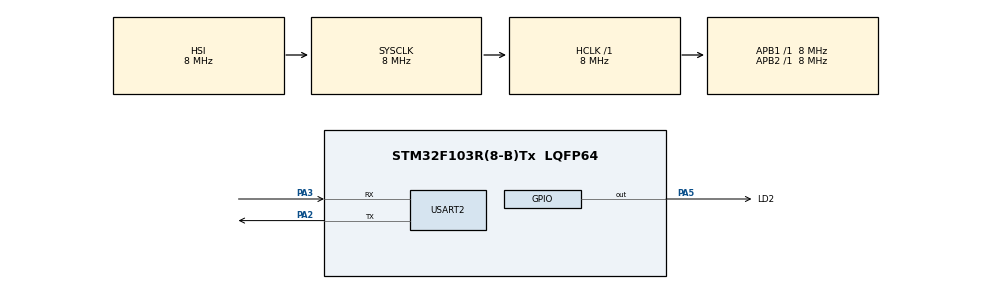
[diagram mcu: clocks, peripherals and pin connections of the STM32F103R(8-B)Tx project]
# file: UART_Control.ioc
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Mcu.Family=STM32F1
Mcu.Name=STM32F103R(8-B)Tx
Mcu.Package=LQFP64
NVIC.PriorityGroup=NVIC_PRIORITYGROUP_4
PA2.Mode=Asynchronous
PA2.Signal=USART2_TX
PA3.Mode=Asynchronous
PA3.Signal=USART2_RX
PA5.GPIO_Label=LD2
PA5.Signal=GPIO_Output
ProjectManager.HeapSize=0x200
ProjectManager.StackSize=0x400
ProjectManager.TargetToolchain=STM32CubeIDE
RCC.AHBFreq_Value=8000000
RCC.APB1Freq_Value=8000000
RCC.APB1TimFreq_Value=8000000
RCC.APB2Freq_Value=8000000
RCC.APB2TimFreq_Value=8000000
RCC.HCLKFreq_Value=8000000
RCC.SYSCLKFreq_VALUE=8000000
RCC.USBFreq_Value=8000000
USART2.VirtualMode=VM_ASYNC
VP_SYS_VS_ND.Mode=No_Debug
board=custom

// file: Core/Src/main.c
/* USER CODE BEGIN Header */
/**
  ******************************************************************************
  * @file           : main.c
  * @brief          : 01_UART_Control - LED control over USART2
  ******************************************************************************
  * @attention
  *
  * Copyright (c) 2026 STMicroelectronics.
  * All rights reserved.
  *
  ******************************************************************************
  */
/* USER CODE END Header */

#include "main.h"
#include <string.h>

UART_HandleTypeDef huart2;

void SystemClock_Config(void);
static void MX_GPIO_Init(void);
static void MX_USART2_UART_Init(void);

int main(void)
{

  HAL_Init();

  SystemClock_Config();

  MX_GPIO_Init();
  MX_USART2_UART_Init();
  /* USER CODE BEGIN 2 */
  const char *welcome = "\r\n=== 01_UART_Control ===\r\n"
                        "Send '1' to switch LED ON, '0' to switch LED OFF.\r\n";
  HAL_UART_Transmit(&huart2, (uint8_t *)welcome, strlen(welcome), HAL_MAX_DELAY);
  /* USER CODE END 2 */

  /* Infinite loop */
  /* USER CODE BEGIN WHILE */
  uint8_t rx;
  while (1)
  {
    if (HAL_UART_Receive(&huart2, &rx, 1, HAL_MAX_DELAY) == HAL_OK)
    {
      if (rx == '1')
      {
        HAL_GPIO_WritePin(LD2_GPIO_Port, LD2_Pin, GPIO_PIN_SET);
        HAL_UART_Transmit(&huart2, (uint8_t *)"LED: ON\r\n", 9, HAL_MAX_DELAY);
      }
      else if (rx == '0')
      {
        HAL_GPIO_WritePin(LD2_GPIO_Port, LD2_Pin, GPIO_PIN_RESET);
        HAL_UART_Transmit(&huart2, (uint8_t *)"LED: OFF\r\n", 10, HAL_MAX_DELAY);
      }
      else
      {
        HAL_UART_Transmit(&huart2, (uint8_t *)"Enter '1' or '0'\r\n", 18, HAL_MAX_DELAY);
      }
    }
    /* USER CODE END WHILE */

  }
}

void SystemClock_Config(void)
{
  RCC_OscInitTypeDef RCC_OscInitStruct = {0};
  RCC_ClkInitTypeDef RCC_ClkInitStruct = {0};

  /** Initializes the RCC Oscillators according to the specified parameters
  */
  RCC_OscInitStruct.OscillatorType = RCC_OSCILLATORTYPE_HSI;
  RCC_OscInitStruct.HSIState = RCC_HSI_ON;
  RCC_OscInitStruct.HSICalibrationValue = RCC_HSICALIBRATION_DEFAULT;
  RCC_OscInitStruct.PLL.PLLState = RCC_PLL_NONE;
  if (HAL_RCC_OscConfig(&RCC_OscInitStruct) != HAL_OK)
  {
    Error_Handler();
  }

  /** Initializes the CPU, AHB and APB buses clocks
  */
  RCC_ClkInitStruct.ClockType = RCC_CLOCKTYPE_HCLK|RCC_CLOCKTYPE_SYSCLK
                              |RCC_CLOCKTYPE_PCLK1|RCC_CLOCKTYPE_PCLK2;
  RCC_ClkInitStruct.SYSCLKSource = RCC_SYSCLKSOURCE_HSI;
  RCC_ClkInitStruct.AHBCLKDivider = RCC_SYSCLK_DIV1;
  RCC_ClkInitStruct.APB1CLKDivider = RCC_HCLK_DIV1;
  RCC_ClkInitStruct.APB2CLKDivider = RCC_HCLK_DIV1;

  if (HAL_RCC_ClockConfig(&RCC_ClkInitStruct, FLASH_LATENCY_0) != HAL_OK)
  {
    Error_Handler();
  }
}

static void MX_USART2_UART_Init(void)
{
  huart2.Instance = USART2;
  huart2.Init.BaudRate = 115200;
  huart2.Init.WordLength = UART_WORDLENGTH_8B;
  huart2.Init.StopBits = UART_STOPBITS_1;
  huart2.Init.Parity = UART_PARITY_NONE;
  huart2.Init.Mode = UART_MODE_TX_RX;
  huart2.Init.HwFlowCtl = UART_HWCONTROL_NONE;
  huart2.Init.OverSampling = UART_OVERSAMPLING_16;
  if (HAL_UART_Init(&huart2) != HAL_OK)
  {
    Error_Handler();
  }
}

static void MX_GPIO_Init(void)
{
  GPIO_InitTypeDef GPIO_InitStruct = {0};

  /* GPIO Ports Clock Enable */
  __HAL_RCC_GPIOA_CLK_ENABLE();

  /*Configure GPIO pin Output Level */
  HAL_GPIO_WritePin(LD2_GPIO_Port, LD2_Pin, GPIO_PIN_RESET);

  /*Configure GPIO pin : LD2_Pin */
  GPIO_InitStruct.Pin = LD2_Pin;
  GPIO_InitStruct.Mode = GPIO_MODE_OUTPUT_PP;
  GPIO_InitStruct.Pull = GPIO_NOPULL;
  GPIO_InitStruct.Speed = GPIO_SPEED_FREQ_LOW;
  HAL_GPIO_Init(LD2_GPIO_Port, &GPIO_InitStruct);
}

void Error_Handler(void)
{
  __disable_irq();
  while (1)
  {
  }
}

#ifdef USE_FULL_ASSERT
/**
  * @brief  Reports the name of the source file and the source line number
  * @param  file: pointer to the source file name
  * @param  line: assert_param error line source number
  * @retval None
  */
void assert_failed(uint8_t *file, uint32_t line)
{
  /* USER CODE BEGIN 6 */
  (void)file;
  (void)line;
  /* USER CODE END 6 */
}
#endif /* USE_FULL_ASSERT */
